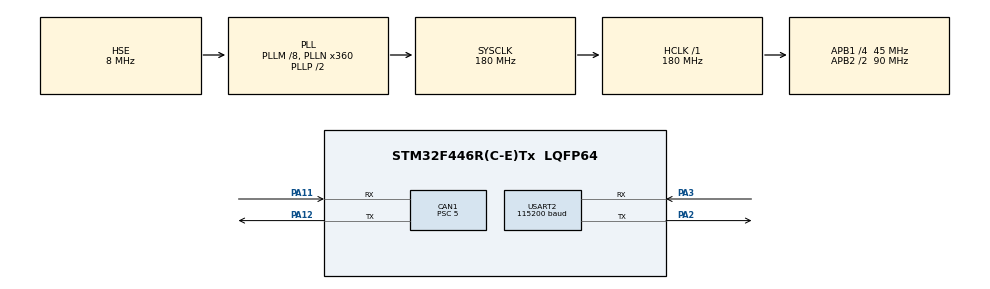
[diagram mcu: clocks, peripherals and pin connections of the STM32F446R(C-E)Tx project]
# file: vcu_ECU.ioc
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CAN1.ABOM=ENABLE
CAN1.BS1=CAN_BS1_15TQ
CAN1.BS2=CAN_BS2_2TQ
CAN1.CalculateBaudRate=500000
CAN1.CalculateTimeBit=2000
CAN1.CalculateTimeQuantum=111.11111111111111
CAN1.Mode=CAN_MODE_NORMAL
CAN1.NART=ENABLE
CAN1.Prescaler=5
FREERTOS.Tasks01=defaultTask,24,128,StartDefaultTask,Default,NULL,Dynamic,NULL,NULL;VCUCtrlTask,24,256,StartVCUCtrlTask,Default,NULL,Dynamic,NULL,NULL;VCUTxTask,32,256,StartVCUTxTask,Default,NULL,Dynamic,NULL,NULL
FREERTOS.configCHECK_FOR_STACK_OVERFLOW=2
FREERTOS.configUSE_MALLOC_FAILED_HOOK=1
FREERTOS.configUSE_NEWLIB_REENTRANT=1
Mcu.Family=STM32F4
Mcu.Name=STM32F446R(C-E)Tx
Mcu.Package=LQFP64
NVIC.CAN1_RX0_IRQn=true\:6\:0\:true\:false\:true\:true\:true\:true\:true
NVIC.PriorityGroup=NVIC_PRIORITYGROUP_4
NVIC.TIM6_DAC_IRQn=true\:15\:0\:false\:false\:true\:false\:false\:true\:true
NVIC.TimeBase=TIM6_DAC_IRQn
NVIC.TimeBaseIP=TIM6
NVIC.USART2_IRQn=true\:6\:0\:true\:false\:true\:true\:true\:true\:true
PA11.Mode=CAN_Activate
PA11.Signal=CAN1_RX
PA12.Mode=CAN_Activate
PA12.Signal=CAN1_TX
PA13.Mode=Serial_Wire
PA13.Signal=SYS_JTMS-SWDIO
PA14.Mode=Serial_Wire
PA14.Signal=SYS_JTCK-SWCLK
PA2.Mode=Asynchronous
PA2.Signal=USART2_TX
PA3.Mode=Asynchronous
PA3.Signal=USART2_RX
ProjectManager.HeapSize=0x200
ProjectManager.StackSize=0x400
ProjectManager.TargetToolchain=STM32CubeIDE
RCC.AHBFreq_Value=180000000
RCC.APB1CLKDivider=RCC_HCLK_DIV4
RCC.APB1Freq_Value=45000000
RCC.APB1TimFreq_Value=90000000
RCC.APB2CLKDivider=RCC_HCLK_DIV2
RCC.APB2Freq_Value=90000000
RCC.APB2TimFreq_Value=180000000
RCC.CortexFreq_Value=180000000
RCC.HCLKFreq_Value=180000000
RCC.PLLM=8
RCC.PLLN=360
RCC.HSE_VALUE=8000000
RCC.HSEState=RCC_HSE_BYPASS
RCC.HSIState=RCC_HSI_ON
RCC.OscillatorType=RCC_OSCILLATORTYPE_HSI|RCC_OSCILLATORTYPE_HSE
RCC.PLLSourceVirtual=RCC_PLLSOURCE_HSE
RCC.SYSCLKFreq_VALUE=180000000
RCC.SYSCLKSource=RCC_SYSCLKSOURCE_PLLCLK
RCC.USBFreq_Value=180000000
RCC.VCOOutputFreq_Value=360000000
TIM2.Prescaler=89
USART2.BaudRate=115200
USART2.Mode=MODE_TX_RX
USART2.OverSampling=UART_OVERSAMPLING_16
USART2.Parity=PARITY_NONE
USART2.StopBits=STOPBITS_1
USART2.VirtualMode=VM_ASYNC
USART2.VirtualMode-Asynchronous=VM_ASYNC
USART2.WordLength=WORDLENGTH_8B
VP_FREERTOS_VS_CMSIS_V2.Mode=CMSIS_V2
VP_SYS_VS_tim6.Mode=TIM6
VP_TIM2_VS_ClockSourceINT.Mode=Internal
board=custom

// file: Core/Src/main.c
/* USER CODE BEGIN Header */
/**
  ******************************************************************************
  * @file           : main.c
  * @brief          : Main program body
  ******************************************************************************
  * @attention
  *
  * Copyright (c) 2026 STMicroelectronics.
  * All rights reserved.
  *
  * This software is licensed under terms that can be found in the LICENSE file
  * in the root directory of this software component.
  * If no LICENSE file comes with this software, it is provided AS-IS.
  *
  ******************************************************************************
  */
/* USER CODE END Header */
#include "main.h"
#include "cmsis_os.h"
#include "can.h"
#include "tim.h"
#include "usart.h"
#include "gpio.h"

/* USER CODE BEGIN Includes */
#include "vcu_serial.h"

/* USER CODE END Includes */

void SystemClock_Config(void);
void MX_FREERTOS_Init(void);

int main(void)
{

  /* MCU Configuration--------------------------------------------------------*/

  /* Reset of all peripherals, Initializes the Flash interface and the Systick. */
  HAL_Init();

  /* Configure the system clock */
  SystemClock_Config();

  /* Initialize all configured peripherals */
  MX_GPIO_Init();
  MX_CAN1_Init();
  MX_USART2_UART_Init();
  MX_TIM2_Init();
  /* USER CODE BEGIN 2 */

  /* CAN and the PC diagnostic UART are independent links. Keep the UART
   * receive/ACK path available even when CAN hardware is not ready.
   */
  (void)VCU_CAN_Start();
  vcu_serial_start();

  /* USER CODE END 2 */

  /* Init scheduler */
  osKernelInitialize();  /* Call init function for freertos objects (in cmsis_os2.c) */
  MX_FREERTOS_Init();

  /* Start scheduler */
  osKernelStart();

  /* We should never get here as control is now taken by the scheduler */

  /* Infinite loop */
  while (1)
  {

  }
}

void SystemClock_Config(void)
{
  RCC_OscInitTypeDef RCC_OscInitStruct = {0};
  RCC_ClkInitTypeDef RCC_ClkInitStruct = {0};

  /** Configure the main internal regulator output voltage
  */
  __HAL_RCC_PWR_CLK_ENABLE();
  __HAL_PWR_VOLTAGESCALING_CONFIG(PWR_REGULATOR_VOLTAGE_SCALE1);

  /** Initializes the RCC Oscillators according to the specified parameters
  * in the RCC_OscInitTypeDef structure.
  */
  RCC_OscInitStruct.OscillatorType = RCC_OSCILLATORTYPE_HSI | RCC_OSCILLATORTYPE_HSE;
  RCC_OscInitStruct.HSIState = RCC_HSI_ON;
  RCC_OscInitStruct.HSICalibrationValue = RCC_HSICALIBRATION_DEFAULT;
  RCC_OscInitStruct.HSEState = RCC_HSE_BYPASS;
  RCC_OscInitStruct.PLL.PLLState = RCC_PLL_ON;
  RCC_OscInitStruct.PLL.PLLSource = RCC_PLLSOURCE_HSE;
  RCC_OscInitStruct.PLL.PLLM = 8;
  RCC_OscInitStruct.PLL.PLLN = 360;
  RCC_OscInitStruct.PLL.PLLP = RCC_PLLP_DIV2;
  RCC_OscInitStruct.PLL.PLLQ = 2;
  RCC_OscInitStruct.PLL.PLLR = 2;
  if (HAL_RCC_OscConfig(&RCC_OscInitStruct) != HAL_OK)
  {
    Error_Handler();
  }

  /** Activate the Over-Drive mode
  */
  if (HAL_PWREx_EnableOverDrive() != HAL_OK)
  {
    Error_Handler();
  }

  /** Initializes the CPU, AHB and APB buses clocks
  */
  RCC_ClkInitStruct.ClockType = RCC_CLOCKTYPE_HCLK|RCC_CLOCKTYPE_SYSCLK
                              |RCC_CLOCKTYPE_PCLK1|RCC_CLOCKTYPE_PCLK2;
  RCC_ClkInitStruct.SYSCLKSource = RCC_SYSCLKSOURCE_PLLCLK;
  RCC_ClkInitStruct.AHBCLKDivider = RCC_SYSCLK_DIV1;
  RCC_ClkInitStruct.APB1CLKDivider = RCC_HCLK_DIV4;
  RCC_ClkInitStruct.APB2CLKDivider = RCC_HCLK_DIV2;

  if (HAL_RCC_ClockConfig(&RCC_ClkInitStruct, FLASH_LATENCY_5) != HAL_OK)
  {
    Error_Handler();
  }
}

void HAL_TIM_PeriodElapsedCallback(TIM_HandleTypeDef *htim)
{
  if (htim->Instance == TIM6)
  {
    HAL_IncTick();
  }
}

void Error_Handler(void)
{
  __disable_irq();
  while (1)
  {
  }
}

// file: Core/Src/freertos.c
/* USER CODE BEGIN Header */
/**
  ******************************************************************************
  * File Name          : freertos.c
  * Description        : Code for freertos applications
  ******************************************************************************
  * @attention
  *
  * Copyright (c) 2026 STMicroelectronics.
  * All rights reserved.
  *
  * This software is licensed under terms that can be found in the LICENSE file
  * in the root directory of this software component.
  * If no LICENSE file comes with this software, it is provided AS-IS.
  *
  ******************************************************************************
  */
/* USER CODE END Header */

#include "FreeRTOS.h"
#include "task.h"
#include "main.h"
#include "cmsis_os.h"

/* USER CODE BEGIN Includes */
#include "vcu_task.h"
#include "vcu_serial.h"

/* USER CODE END Includes */

/* Definitions for defaultTask */
osThreadId_t defaultTaskHandle;
const osThreadAttr_t defaultTask_attributes = {
  .name = "defaultTask",
  .stack_size = 128 * 4,
  .priority = (osPriority_t) osPriorityNormal,
};
/* Definitions for VCUCtrlTask */
osThreadId_t VCUCtrlTaskHandle;
const osThreadAttr_t VCUCtrlTask_attributes = {
  .name = "VCUCtrlTask",
  .stack_size = 256 * 4,
  .priority = (osPriority_t) osPriorityNormal,
};
/* Definitions for VCUTxTask */
osThreadId_t VCUTxTaskHandle;
const osThreadAttr_t VCUTxTask_attributes = {
  .name = "VCUTxTask",
  .stack_size = 256 * 4,
  .priority = (osPriority_t) osPriorityAboveNormal,
};

void StartDefaultTask(void *argument);
void StartVCUCtrlTask(void *argument);
void StartVCUTxTask(void *argument);

void MX_FREERTOS_Init(void); /* (MISRA C 2004 rule 8.1) */

/* Hook prototypes */
void vApplicationStackOverflowHook(xTaskHandle xTask, signed char *pcTaskName);
void vApplicationMallocFailedHook(void);

/* USER CODE BEGIN 4 */
void vApplicationStackOverflowHook(xTaskHandle xTask, signed char *pcTaskName)
{
   /* Run time stack overflow checking is performed if
   configCHECK_FOR_STACK_OVERFLOW is defined to 1 or 2. This hook function is
   called if a stack overflow is detected. */
    (void)xTask;
    (void)pcTaskName;

    taskDISABLE_INTERRUPTS();

    for (;;)
    {
        /* Stack overflow detected */
    }
}
/* USER CODE END 4 */

/* USER CODE BEGIN 5 */
void vApplicationMallocFailedHook(void)
{
   /* vApplicationMallocFailedHook() will only be called if
   configUSE_MALLOC_FAILED_HOOK is set to 1 in FreeRTOSConfig.h. It is a hook
   function that will get called if a call to pvPortMalloc() fails.
   pvPortMalloc() is called internally by the kernel whenever a task, queue,
   timer or semaphore is created. It is also called by various parts of the
   demo application. If heap_1.c or heap_2.c are used, then the size of the
   heap available to pvPortMalloc() is defined by configTOTAL_HEAP_SIZE in
   FreeRTOSConfig.h, and the xPortGetFreeHeapSize() API function can be used
   to query the size of free heap space that remains (although it does not
   provide information on how the remaining heap might be fragmented). */
    taskDISABLE_INTERRUPTS();

    for (;;)
    {
        /* FreeRTOS memory allocation failed */
    }
}
/* USER CODE END 5 */

void MX_FREERTOS_Init(void) {

  /* Create the thread(s) */
  /* creation of defaultTask */
  defaultTaskHandle = osThreadNew(StartDefaultTask, NULL, &defaultTask_attributes);

  /* creation of VCUCtrlTask */
  VCUCtrlTaskHandle = osThreadNew(StartVCUCtrlTask, NULL, &VCUCtrlTask_attributes);

  /* creation of VCUTxTask */
  VCUTxTaskHandle = osThreadNew(StartVCUTxTask, NULL, &VCUTxTask_attributes);

}

void StartDefaultTask(void *argument)
{
  for(;;)
  {
    osDelay(1);
  }
}

void StartVCUCtrlTask(void *argument)
{
  /* USER CODE BEGIN StartVCUCtrlTask */
  (void)argument;
  vcu_serial_task_run();
  /* USER CODE END StartVCUCtrlTask */
}

void StartVCUTxTask(void *argument)
{
  /* USER CODE BEGIN StartVCUTxTask */
  (void)argument;
  vcu_task_run();
  /* USER CODE END StartVCUTxTask */
}
